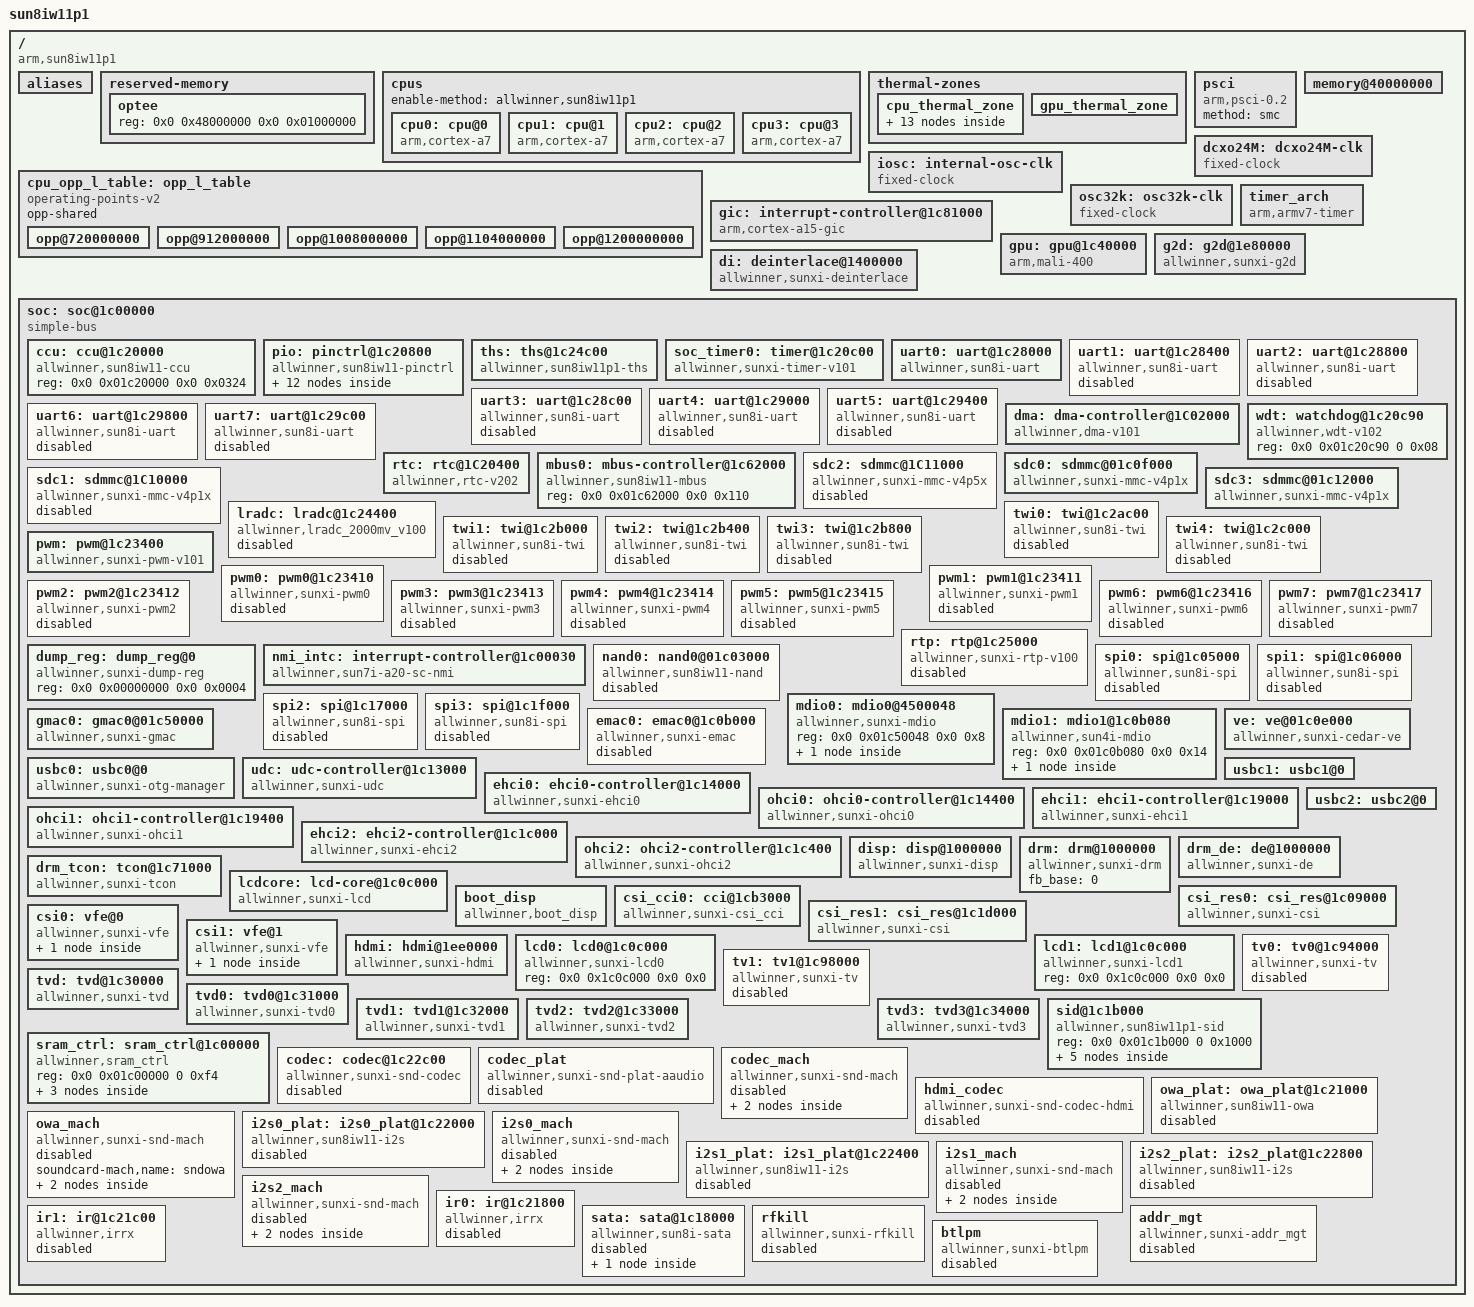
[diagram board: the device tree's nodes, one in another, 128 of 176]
/*
 * Allwinner Technology CO., Ltd. sun8iw11p1 platform
 *
 * fpga support
 * modify base on juno.dts & sun8iw10
 */
/* kernel used */
/memreserve/ 0x43000000 0x00000800; /* super standby range  : [0x43000000~0x43000800], size = 2K  */
/memreserve/ 0x47A00000 0x100000; /* ion carvout heap revserve  : [0x58000000~0x68000000], size = 256M  */

#include <dt-bindings/interrupt-controller/arm-gic.h>
#include <dt-bindings/gpio/gpio.h>
#include <dt-bindings/display/lcd_command.h>
#include <dt-bindings/clock/sun8iw11-ccu.h>
#include <dt-bindings/reset/sun8iw11-ccu.h>

/ {
	model = "sun8iw11p1";
	compatible = "arm,sun8iw11p1", "arm,sun8iw11p1";
	interrupt-parent = <&gic>;
	#address-cells = <2>;
	#size-cells = <2>;

	aliases {
		serial0 = &uart0;
		serial1 = &uart1;
		serial2 = &uart2;
		serial3 = &uart3;
		serial4 = &uart4;
		serial5 = &uart5;
		serial6 = &uart6;
		serial7 = &uart7;
		spi0 = &spi0;
		spi1 = &spi1;
		spi2 = &spi2;
		spi3 = &spi3;
		pio = &pio;
		pwm = &pwm;
		pwm0 = &pwm0;
		pwm1 = &pwm1;
		pwm2 = &pwm2;
		pwm3 = &pwm3;
		pwm4 = &pwm4;
		pwm5 = &pwm5;
		pwm6 = &pwm6;
		pwm7 = &pwm7;
		twi0 = &twi0;
		twi1 = &twi1;
		twi2 = &twi2;
		twi3 = &twi3;
		twi4 = &twi4;
		sunxi-mmc0 = &sdc0;
		sunxi-mmc2 = &sdc2;
		disp = &disp;
		lcd0 = &lcd0;
		lcd1 = &lcd1;
		tv0 = &tv0;
		tv1 = &tv1;
		boot_disp = &boot_disp;
		hdmi = &hdmi;
		drm = &drm;
		ir0 = &ir0;
		ir1 = &ir1;
		sata = &sata;
		nand0 = &nand0;
		cci0 = &csi_cci0;
		csi_res0 = &csi_res0;
		csi_res1 = &csi_res1;
		vfe0 = &csi0;
		vfe1 = &csi1;
		gmac0 = &gmac0;
		emac0 = &emac0;
	};

	reserved-memory {
		#address-cells = <2>;
		#size-cells = <2>;
		ranges;

		optee {
			reg = <0x0 0x48000000 0x0 0x01000000>;
		};
	};

	cpus {
		enable-method = "allwinner,sun8iw11p1";
		#address-cells = <1>;
		#size-cells = <0>;

		cpu0: cpu@0 {
			device_type = "cpu";
			compatible = "arm,cortex-a7","arm,armv7";
			reg = <0x0>;
			enable-method = "psci";
			clocks = <&ccu CLK_CPUX>;
			clock-latency = <2000000>;
			clock-frequency = <1008000000>;
			operating-points-v2 = <&cpu_opp_l_table>;
			#cooling-cells = <2>;
		};

		cpu1: cpu@1 {
			device_type = "cpu";
			compatible = "arm,cortex-a7","arm,armv7";
			reg = <0x1>;
			enable-method = "psci";
			clocks = <&ccu CLK_CPUX>;
			clock-frequency = <1008000000>;
			operating-points-v2 = <&cpu_opp_l_table>;
			#cooling-cells = <2>;
		};

		cpu2: cpu@2 {
			device_type = "cpu";
			compatible = "arm,cortex-a7","arm,armv7";
			reg = <0x2>;
			enable-method = "psci";
			clocks = <&ccu CLK_CPUX>;
			clock-frequency = <1008000000>;
			operating-points-v2 = <&cpu_opp_l_table>;
			#cooling-cells = <2>;
		};

		cpu3: cpu@3 {
			device_type = "cpu";
			compatible = "arm,cortex-a7","arm,armv7";
			reg = <0x3>;
			enable-method = "psci";
			clocks = <&ccu CLK_CPUX>;
			clock-frequency = <1008000000>;
			operating-points-v2 = <&cpu_opp_l_table>;
			#cooling-cells = <2>;
		};
	};

	cpu_opp_l_table: opp_l_table {
		compatible = "operating-points-v2";
		opp-shared;

		opp@720000000 {
			opp-hz = /bits/ 64 <720000000>;
			opp-microvolt = <1060000>;
			clock-latency-ns = <244144>; /* 8 32k periods */
		};
		opp@912000000 {
			opp-hz = /bits/ 64 <912000000>;
			opp-microvolt = <1160000>;
			clock-latency-ns = <244144>; /* 8 32k periods */
		};
		opp@1008000000 {
			opp-hz = /bits/ 64 <1008000000>;
			opp-microvolt = <1220000>;
			clock-latency-ns = <244144>; /* 8 32k periods */
		};
		opp@1104000000 {
			opp-hz = /bits/ 64 <1104000000>;
			opp-microvolt = <1300000>;
			clock-latency-ns = <244144>; /* 8 32k periods */
		};
		opp@1200000000 {
			opp-hz = /bits/ 64 <1200000000>;
			opp-microvolt = <1360000>;
			clock-latency-ns = <244144>; /* 8 32k periods */
		};
	};

	thermal-zones {
		cpu_thermal_zone {
			polling-delay-passive = <1000>;
			polling-delay = <10000>;
			thermal-sensors = <&ths 0>;

			trips {
				cpu_trip0: t0 {
					temperature = <95000>;
					hysteresis = <0>;
					type = "passive";
				};

				cpu_trip1: t1 {
					temperature = <105000>;
					hysteresis = <0>;
					type = "passive";
				};

				cpu_trip2: t2 {
					temperature = <112000>;
					hysteresis = <0>;
					type = "passive";
				};

				cpu_trip3: t3 {
					temperature = <114000>;
					hysteresis = <0>;
					type = "passive";
				};

				cpu_trip4: t4 {
					temperature = <117000>;
					hysteresis = <0>;
					type = "passive";
				};

				crt_trip0: t5 {
					temperature = <120000>;
					hysteresis = <0>;
					type = "critical";
				};
			};

			cooling-maps {
				map0 {
					trip = <&cpu_trip0>;
					cooling-device = <&cpu0 1 1>,
							 <&cpu1 1 1>,
							 <&cpu2 1 1>,
							 <&cpu3 1 1>;
				};

				map1 {
					trip = <&cpu_trip1>;
					cooling-device = <&cpu0 2 2>,
							 <&cpu1 2 2>,
							 <&cpu2 2 2>,
							 <&cpu3 2 2>;
				};

				map2 {
					trip = <&cpu_trip2>;
					cooling-device = <&cpu0 3 3>,
							 <&cpu1 3 3>,
							 <&cpu2 3 3>,
							 <&cpu3 3 3>;
				};

				map3 {
					trip = <&cpu_trip3>;
					cooling-device = <&cpu0 4 4>,
							 <&cpu1 4 4>,
							 <&cpu2 4 4>,
							 <&cpu3 4 4>;
				};

				map4 {
					trip = <&cpu_trip4>;
					cooling-device = <&cpu0 5 5>,
							 <&cpu1 5 5>,
							 <&cpu2 5 5>,
							 <&cpu3 5 5>;
				};
			};
		};

		gpu_thermal_zone {
			polling-delay-passive = <1000>;
			polling-delay = <10000>;
			thermal-sensors = <&ths 1>;
		};
	};

	psci {
		compatible = "arm,psci-0.2";
		method = "smc";
	};

	memory@40000000 {
		device_type = "memory";
		reg = <0x00000000 0x40000000 0x00000000 0x08000000>;
	};

	dcxo24M: dcxo24M-clk {
		#clock-cells = <0>;
		compatible = "fixed-clock";
		clock-frequency = <24000000>;
		clock-output-names = "dcxo24M";
	};
	iosc: internal-osc-clk {
		#clock-cells = <0>;
		compatible = "fixed-clock";
		clock-frequency = <16000000>;
		clock-accuracy = <300000000>;
		clock-output-names = "iosc";
	};

	osc32k: osc32k-clk {
		#clock-cells = <0>;
		compatible = "fixed-clock";
		clock-frequency = <32768>;
		clock-output-names = "osc32k";
	};

	gic: interrupt-controller@1c81000 {
		compatible = "arm,cortex-a15-gic", "arm,cortex-a9-gic";
		#interrupt-cells = <3>;
		#address-cells = <0>;
		device_type = "gic";
		interrupt-controller;
		reg = <0x0 0x01c81000 0 0x1000>, /* GIC Dist */
			 <0x0 0x01c82000 0 0x2000>, /* GIC CPU */
			 <0x0 0x01c84000 0 0x2000>, /* GIC VCPU Control */
			 <0x0 0x01c86000 0 0x2000>; /* GIC VCPU */
		interrupts = <GIC_PPI 9 0xf04>; /* GIC Maintenence IRQ */
		interrupt-parent = <&gic>;
	};

	timer_arch {
		compatible = "arm,armv7-timer";
		interrupts = <GIC_PPI 13 (GIC_CPU_MASK_SIMPLE(4) | IRQ_TYPE_LEVEL_LOW)>,
			     <GIC_PPI 14 (GIC_CPU_MASK_SIMPLE(4) | IRQ_TYPE_LEVEL_LOW)>;
		clock-frequency = <24000000>;
		arm,cpu-registers-not-fw-configured;
		interrupt-parent = <&gic>;
		arm,no-tick-in-suspend;
	};

	gpu: gpu@1c40000 {
		compatible = "arm,mali-400", "arm,mali-utgard";
		reg = <0x0 0x01c40000 0x0 0x10000>;
		interrupts = <GIC_SPI 69 IRQ_TYPE_LEVEL_HIGH>,
					<GIC_SPI 70 IRQ_TYPE_LEVEL_HIGH>,
					<GIC_SPI 71 IRQ_TYPE_LEVEL_HIGH>,
					<GIC_SPI 72 IRQ_TYPE_LEVEL_HIGH>,
					<GIC_SPI 74 IRQ_TYPE_LEVEL_HIGH>,
					<GIC_SPI 75 IRQ_TYPE_LEVEL_HIGH>;
		interrupt-names = "IRQGP", "IRQGPMMU", "IRQPP0", "IRQPPMMU0", "IRQPP1", "IRQPPMMU1";
		clocks = <&ccu CLK_BUS_GPU>, <&ccu CLK_PLL_GPU>, <&ccu CLK_GPU>;
		clock-names = "bus", "pll", "core";
		resets = <&ccu RST_BUS_GPU>;
	};

	g2d: g2d@1e80000 {
		compatible = "allwinner,sunxi-g2d";
		reg = <0x0 0x01e80000 0x0 0x800>;
		interrupts = <GIC_SPI 46 IRQ_TYPE_LEVEL_HIGH>;
		clocks = <&ccu CLK_BUS_MP>, <&ccu CLK_DE_MP>, <&ccu CLK_MP_GATE>;
		clock-names = "bus", "g2d", "mbus_g2d";

		resets = <&ccu RST_BUS_MP>;
		reset-names = "rst_bus_mp";

		assigned-clocks = <&ccu CLK_DE_MP>;
		assigned-clock-parents = <&ccu CLK_PLL_DE>;
		assigned-clock-rates = <297000000>;
		status = "okay";
	};

	di:deinterlace@1400000{
		#address-cells = <1>;
		#size-cells = <0>;
		compatible = "allwinner,sunxi-deinterlace";
		reg = <0x0 0x01400000 0x0 0x77c>;
		interrupts = <GIC_SPI 93 IRQ_TYPE_LEVEL_HIGH>;
		status = "okay";

		clocks = <&ccu CLK_DEINTERLACE>,
			 <&ccu CLK_BUS_DI>,
			 <&ccu CLK_PLL_PERIPH0_1X>,
			 <&ccu CLK_DI_GATE>;
		clock-names = "clk_di",
			      "clk_bus_di",
			      "clk_pll_di",
			      "dclk_gate_di";
		resets = <&ccu RST_BUS_DI>;
		reset-names = "rst_bus_di";

		assigned-clocks = <&ccu CLK_DEINTERLACE>;
		assigned-clock-parents = <&ccu CLK_PLL_PERIPH0_1X>;
	};

	soc: soc@1c00000 {
		compatible = "simple-bus";
		#address-cells = <2>;
		#size-cells = <2>;
		ranges;
		device_type = "soc";

		ccu: ccu@1c20000 {
			compatible = "allwinner,sun8iw11-ccu";
			reg = <0x0 0x01c20000 0x0 0x0324>;  /*cpux space*/
			#clock-cells = <1>;
			#reset-cells = <1>;
		};

		pio: pinctrl@1c20800 {
			compatible = "allwinner,sun8iw11-pinctrl";
			reg = <0x0 0x01c20800 0x0 0x400>;
			interrupts = <GIC_SPI 28 IRQ_TYPE_LEVEL_HIGH>;
			clocks = <&ccu CLK_APB1>, <&dcxo24M>, <&ccu CLK_BUS_PIO>;
			clock-names = "apb", "hosc", "bus";
			gpio-controller;
			#gpio-cells = <3>;
			interrupt-controller;
			#interrupt-cells = <3>;

			lvds0_pins_a: lvds0@0 {
				pins = "PD0", "PD1", "PD2", "PD3", "PD4", "PD5", "PD8", "PD9", "PD6", "PD7";
				function = "lvds0";
				drive-strength = <30>;
			};

			lvds0_pins_b: lvds0@1 {
				pins = "PD0", "PD1", "PD2", "PD3", "PD4", "PD5", "PD8", "PD9", "PD6", "PD7";
				function = "gpio_in";
			};

			lvds1_pins_a: lvds1@0 {
				pins = "PD10", "PD11", "PD12", "PD13", "PD14", "PD15", "PD18", "PD19", "PD16", "PD17";
				function = "lvds1";
				drive-strength = <30>;
			};
			lvds1_pins_b: lvds1@1 {
				pins = "PD10", "PD11", "PD12", "PD13", "PD14", "PD15", "PD18", "PD19", "PD16", "PD17";
				function = "gpio_in";
			};

			csi0_pins_a: csi0@0 {
				pins = "PE0", "PE2", "PE3", "PE4",
						 "PE5", "PE6", "PE7", "PE8",
						 "PE9", "PE10", "PE11";
				function = "csi0";
				drive-strength = <20>;
			};

			csi0_pins_b: csi0@1 {
				pins = "PE0", "PE2", "PE3", "PE4",
						 "PE5", "PE6", "PE7", "PE8",
						 "PE9", "PE10", "PE11";
				function = "io_disabled";
			};

			csi_mclk0_pins_a: csi_mclk0@0 {
				pins = "PE1";
				function = "csi0";
				drive-strength = <20>;
			};

			csi_mclk0_pins_b: csi_mclk0@1 {
				pins = "PE1";
				function = "gpio_in";
			};

			csi1_pins_a: csi1@0 {
				pins = "PG0", "PG2", "PG3", "PG4",
						 "PG5", "PG6", "PG7", "PG8",
						 "PG9", "PG10", "PG11";
				function = "csi1";
				drive-strength = <10>;
			};

			csi1_pins_b: csi1@1 {
				pins = "PG0", "PG2", "PG3", "PG4",
						 "PG5", "PG6", "PG7", "PG8",
						 "PG9", "PG10", "PG11";
				function = "io_disabled";
			};

			csi_mclk1_pins_a: csi_mclk1@0 {
				pins = "PG1";
				function = "csi1";
				drive-strength = <20>;
			};

			csi_mclk1_pins_b: csi_mclk1@1 {
				pins = "PG1";
				function = "gpio_in";
			};

		};

		ths: ths@1c24c00 {
			compatible = "allwinner,sun8iw11p1-ths";
			reg = <0x0 0x01c24c00 0x0 0x400>;
			clocks = <&ccu CLK_BUS_THS>, <&ccu CLK_THS>;
			clock-names = "bus", "sclk";
			resets = <&ccu RST_BUS_THS>;
			#thermal-sensor-cells = <1>;
		};

		soc_timer0: timer@1c20c00 {
			compatible = "allwinner,sunxi-timer-v101";
			device_type = "soc_timer";
			reg = <0x0 0x01c20c00 0x0 0x90>;
			interrupt-parent = <&gic>;
			interrupts = <GIC_SPI 22 IRQ_TYPE_EDGE_RISING>;
			clocks = <&dcxo24M>;
		};

		uart0: uart@1c28000 {
			compatible = "allwinner,sun8i-uart";
			device_type = "uart0";
			reg = <0x0 0x01c28000 0x0 0x400>;
			interrupts = <GIC_SPI 1 IRQ_TYPE_LEVEL_HIGH>;
			clocks = <&ccu CLK_BUS_UART0>;
			resets = <&ccu RST_BUS_UART0>;
			uart0_port = <0>;
			uart0_type = <2>;
			sunxi,uart-fifosize = <64>;
			status = "okay";
		};

		uart1: uart@1c28400 {
			compatible = "allwinner,sun8i-uart";
			device_type = "uart1";
			reg = <0x0 0x01c28400 0x0 0x400>;
			interrupts = <GIC_SPI 2 IRQ_TYPE_LEVEL_HIGH>;
			clocks = <&ccu CLK_BUS_UART1>;
			resets = <&ccu RST_BUS_UART1>;
			uart1_port = <1>;
			uart1_type = <8>;
			sunxi,uart-fifosize = <64>;
			status = "disabled";
		};

		uart2: uart@1c28800 {
			compatible = "allwinner,sun8i-uart";
			device_type = "uart2";
			reg = <0x0 0x01c28800 0x0 0x400>;
			interrupts = <GIC_SPI 3 IRQ_TYPE_LEVEL_HIGH>;
			clocks = <&ccu CLK_BUS_UART2>;
			resets = <&ccu RST_BUS_UART2>;
			uart2_port = <2>;
			uart2_type = <4>;
			sunxi,uart-fifosize = <64>;
			status = "disabled";
		};

		uart3: uart@1c28c00 {
			compatible = "allwinner,sun8i-uart";
			device_type = "uart3";
			reg = <0x0 0x01c28c00 0x0 0x400>;
			interrupts = <GIC_SPI 4 IRQ_TYPE_LEVEL_HIGH>;
			clocks = <&ccu CLK_BUS_UART3>;
			resets = <&ccu RST_BUS_UART3>;
			uart3_port = <3>;
			uart3_type = <4>;
			sunxi,uart-fifosize = <64>;
			status = "disabled";
		};

		uart4: uart@1c29000 {
			compatible = "allwinner,sun8i-uart";
			device_type = "uart4";
			reg = <0x0 0x01c29000 0x0 0x400>;
			interrupts = <GIC_SPI 17 IRQ_TYPE_LEVEL_HIGH>;
			clocks = <&ccu CLK_BUS_UART4>;
			resets = <&ccu RST_BUS_UART4>;
			uart4_port = <4>;
			uart4_type = <2>;
			sunxi,uart-fifosize = <64>;
			status = "disabled";
		};

		uart5: uart@1c29400 {
			compatible = "allwinner,sun8i-uart";
			device_type = "uart5";
			reg = <0x0 0x01c29400 0x0 0x400>;
			interrupts = <GIC_SPI 18 IRQ_TYPE_LEVEL_HIGH>;
			clocks = <&ccu CLK_BUS_UART5>;
			resets = <&ccu RST_BUS_UART5>;
			uart5_port = <5>;
			uart5_type = <2>;
			sunxi,uart-fifosize = <64>;
			status = "disabled";
		};

		uart6: uart@1c29800 {
			compatible = "allwinner,sun8i-uart";
			device_type = "uart6";
			reg = <0x0 0x01c29800 0x0 0x400>;
			interrupts = <GIC_SPI 19 IRQ_TYPE_LEVEL_HIGH>;
			clocks = <&ccu CLK_BUS_UART6>;
			resets = <&ccu RST_BUS_UART6>;
			uart6_port = <6>;
			uart6_type = <2>;
			sunxi,uart-fifosize = <64>;
			status = "disabled";
		};

		uart7: uart@1c29c00 {
			compatible = "allwinner,sun8i-uart";
			device_type = "uart7";
			reg = <0x0 0x01c29c00 0x0 0x400>;
			interrupts = <GIC_SPI 20 IRQ_TYPE_LEVEL_HIGH>;
			clocks = <&ccu CLK_BUS_UART7>;
			resets = <&ccu RST_BUS_UART7>;
			uart7_port = <7>;
			uart7_type = <2>;
			sunxi,uart-fifosize = <64>;
			status = "disabled";
		};


		dma: dma-controller@1C02000 {
			compatible = "allwinner,dma-v101";
			reg = <0x0 0x01C02000 0x0 0x1000>;
			interrupts = <GIC_SPI 27 IRQ_TYPE_LEVEL_HIGH>;
			clocks = <&ccu CLK_BUS_DMA>;
			clock-names = "bus";
			resets = <&ccu RST_BUS_DMA>;
			dma-channels = <16>;
			dma-requests = <32>;
			#dma-cells = <1>;
		};

		wdt: watchdog@1c20c90 {
			compatible = "allwinner,wdt-v102";
			reg = <0x0 0x01c20c90 0 0x08>;
		};

		rtc: rtc@1C20400 {
			compatible = "allwinner,rtc-v202";
			device_type = "rtc";
			wakeup-source;
			reg = <0x0 0x01C20400 0x0 0x200>;
			interrupts = <GIC_SPI 24 IRQ_TYPE_LEVEL_HIGH>;
			clocks = <&osc32k>;
			clock-names = "r-ahb-rtc";
			gpr_cur_pos = <6>;
		};

		mbus0: mbus-controller@1c62000 {
			compatible = "allwinner,sun8iw11-mbus";
			reg = <0x0 0x01c62000 0x0 0x110>;
			#mbus-cells = <1>;
		};

		sdc2: sdmmc@1C11000 {
			compatible = "allwinner,sunxi-mmc-v4p5x";
			device_type = "sdc2";
			reg = <0x0 0x01C11000 0x0 0x1000>;
			interrupts = <GIC_SPI 34 0x0104>;  /*  */
			clocks = <&dcxo24M>,
			<&ccu CLK_PLL_PERIPH1_2X>,
			<&ccu CLK_MMC2>,
			<&ccu CLK_BUS_MMC2>;
			clock-names = "osc24m","pll_periph","mmc","ahb";
			resets = <&ccu RST_BUS_MMC2>;
			reset-names = "rst";
			pinctrl-names = "default","sleep";
			pinctrl-0 = <&sdc2_pins_a &sdc2_pins_c>;
			pinctrl-1 = <&sdc2_pins_b>;
			bus-width = <8>;
			/*mmc-ddr-1_8v;*/
			/*mmc-hs200-1_8v;*/
			/*mmc-hs400-1_8v;*/
			non-removable;
			/*max-frequency = <200000000>;*/
			max-frequency = <50000000>;
			cd-gpios;
			sunxi-power-save-mode;
			sunxi-dis-signal-vol-sw;
			/*vmmc = "vcc-emmcv";
			vqmmc = "vcc-emmcvq18";
			vdmmc = "none";*/
			/*-- speed mode --*/
			/*sm0: DS26_SDR12*/
			/*sm1: HSSDR52_SDR25*/
			/*sm2: HSDDR52_DDR50*/
			/*sm3: HS200_SDR104*/
			/*sm4: HS400*/
			/*-- frequency point --
			/*f0: CLK_400K*/
			/*f1: CLK_25M*/
			/*f2: CLK_50M*/
			/*f3: CLK_100M*/
			/*f4: CLK_150M*/
			/*f5: CLK_200M*/
			sdc_tm4_sm0_freq0 = <0>;
			sdc_tm4_sm0_freq1 = <0>;
			sdc_tm4_sm1_freq0 = <0x00000000>;
			sdc_tm4_sm1_freq1 = <0>;
			sdc_tm4_sm2_freq0 = <0x00000000>;
			sdc_tm4_sm2_freq1 = <0>;
			sdc_tm4_sm3_freq0 = <0x05000000>;
			sdc_tm4_sm3_freq1 = <0x00000005>;
			sdc_tm4_sm4_freq0 = <0x00050000>;
			sdc_tm4_sm4_freq1 = <0x00000004>;
			/*vmmc-supply = <&reg_3p3v>;*/
			/*vqmc-supply = <&reg_3p3v>;*/
			/*vdmc-supply = <&reg_3p3v>;*/
			/*vmmc = "vcc-card";*/
			/*vqmc = "";*/
			/*vdmc = "";*/
			/*sunxi-power-save-mode;*/
			status = "disabled";
			/*status = "okay";*/

		};

		sdc0: sdmmc@01c0f000 {
			compatible = "allwinner,sunxi-mmc-v4p1x";
			device_type = "sdc0";
			reg = <0x0 0x01c0f000 0x0 0x1000>; /* only sdmmc0 */
			interrupts = <GIC_SPI 32 0x0104>;  /*  */
			clocks =  <&dcxo24M>,
					<&ccu CLK_PLL_PERIPH1_2X>,
					<&ccu CLK_MMC0>,
					<&ccu CLK_BUS_MMC0>;
			clock-names = "osc24m","pll_periph","mmc","ahb";
			resets = <&ccu RST_BUS_MMC0>;
			reset-names = "rst";
			pinctrl-names = "default","sleep";
			pinctrl-0 = <&sdc0_pins_a>;
			pinctrl-1 = <&sdc0_pins_b>;
			max-frequency = <50000000>;
			bus-width = <4>;
			/*cd-inverted*/
			cd-gpios = <&pio PF 6 0 1 2 0>;
			/* vmmc-supply = <&reg_3p3v>;*/
			/* vqmc-supply = <&reg_3p3v>;*/
			/* vdmc-supply = <&reg_3p3v>;*/
			/*vmmc = "vcc-card";*/
			/*vqmc = "";*/
			/*vdmc = "";*/
			/*sd-uhs-sdr50;*/
			/*sd-uhs-ddr50;*/
			/*cap-sdio-irq;*/
			/*keep-power-in-suspend;*/
			/*ignore-pm-notify;*/
			/*sunxi-power-save-mode;*/
			/*sunxi-dly-400k = <1 0 0 0>; */
			/*sunxi-dly-26M  = <1 0 0 0>;*/
			/*sunxi-dly-52M  = <1 0 0 0 1>;*/
			/*sunxi-dly-52M-ddr4  = <1 0 0 0>;*/
			/*sunxi-dly-52M-ddr8  = <1 0 0 0>;*/
			/*sunxi-dly-104M  = <1 0 0 0>;*/
			/*sunxi-dly-208M  = <1 0 0 0>;*/
			/*sunxi-dly-104M-ddr  = <1 0 0 0>;*/
			/*sunxi-dly-208M-ddr  = <1 0 0 0>;*/
			status = "okay";
		};

		sdc1: sdmmc@1C10000 {
			compatible = "allwinner,sunxi-mmc-v4p1x";
			device_type = "sdc1";
			reg = <0x0 0x1C10000 0x0 0x1000>;
			interrupts = <GIC_SPI 33 0x0104>;  /*  */
			clocks = <&dcxo24M>,
			    <&ccu CLK_PLL_PERIPH1_2X>,
			    <&ccu CLK_MMC1>,
			    <&ccu CLK_BUS_MMC1>;
			clock-names = "osc24m","pll_periph","mmc","ahb";
			resets = <&ccu RST_BUS_MMC1>;
			reset-names = "rst";
			pinctrl-names = "default","sleep";
			pinctrl-0 = <&sdc1_pins_a>;
			pinctrl-1 = <&sdc1_pins_b>;
			max-frequency = <50000000>;
			bus-width = <4>;
			/*broken-cd;*/
			/*cd-inverted*/
			/*cd-gpios = <&pio PG 6 6 1 2 0>;*/
			/* vmmc-supply = <&reg_3p3v>;*/
			/* vqmc-supply = <&reg_3p3v>;*/
			/* vdmc-supply = <&reg_3p3v>;*/
			/*vmmc = "vcc-card";*/
			/*vqmc = "";*/
			/*vdmc = "";*/
			/*sd-uhs-sdr50;*/
			/*sd-uhs-ddr50;*/
			/*sd-uhs-sdr104;*/
			/*cap-sdio-irq;*/
			/*keep-power-in-suspend;*/
			/*ignore-pm-notify;*/
			/*sunxi-power-save-mode;*/
			/*sunxi-dly-400k = <1 0 0 0 0>; */
			/*sunxi-dly-26M  = <1 0 0 0 0>;*/
			/*sunxi-dly-52M  = <1 0 0 0 0>;*/
			/*sunxi-dly-52M-ddr4  = <1 0 0 0 2>;*/
			/*sunxi-dly-52M-ddr8  = <1 0 0 0 0>;*/
			/*sunxi-dly-104M  = <1 0 0 0 1>;*/
			/*sunxi-dly-208M  = <1 1 0 0 0>;*/
			/*sunxi-dly-208M  = <1 0 0 0 1>;*/
			/*sunxi-dly-104M-ddr  = <1 0 0 0 0>;*/
			/*sunxi-dly-208M-ddr  = <1 0 0 0 0>;*/
			/*status = "okay";*/
			status = "disabled";
		};

		sdc3: sdmmc@01c12000 {
			compatible = "allwinner,sunxi-mmc-v4p1x";
			device_type = "sdc3";
			reg = <0x0 0x01C12000 0x0 0x1000>;
			interrupts = <GIC_SPI 35 0x0104>;
			clocks =  <&dcxo24M>,
					<&ccu CLK_PLL_PERIPH1_2X>,
					<&ccu CLK_MMC3>,
					<&ccu CLK_BUS_MMC3>;
			clock-names = "osc24m","pll_periph","mmc","ahb";
			resets = <&ccu RST_BUS_MMC3>;
			reset-names = "rst";
			pinctrl-names = "default","sleep";
			pinctrl-0 = <&sdc3_pins_a>;
			pinctrl-1 = <&sdc3_pins_b>;
			max-frequency = <50000000>;
			bus-width = <4>;
			/*cd-inverted*/
			/* vmmc-supply = <&reg_3p3v>;*/
			/* vqmc-supply = <&reg_3p3v>;*/
			/* vdmc-supply = <&reg_3p3v>;*/
			/*vmmc = "vcc-card";*/
			/*vqmc = "";*/
			/*vdmc = "";*/
			/*sd-uhs-sdr50;*/
			/*sd-uhs-ddr50;*/
			/*cap-sdio-irq;*/
			/*keep-power-in-suspend;*/
			/*ignore-pm-notify;*/
			/*sunxi-power-save-mode;*/
			/*sunxi-dly-400k = <1 0 0 0>; */
			/*sunxi-dly-26M  = <1 0 0 0>;*/
			/*sunxi-dly-52M  = <1 0 0 0 1>;*/
			/*sunxi-dly-52M-ddr4  = <1 0 0 0>;*/
			/*sunxi-dly-52M-ddr8  = <1 0 0 0>;*/
			/*sunxi-dly-104M  = <1 0 0 0>;*/
			/*sunxi-dly-208M  = <1 0 0 0>;*/
			/*sunxi-dly-104M-ddr  = <1 0 0 0>;*/
			/*sunxi-dly-208M-ddr  = <1 0 0 0>;*/
			status = "okay";
		};

		lradc: lradc@1c24400 {
			compatible = "allwinner,lradc_2000mv_v100";
			reg = <0x0 0x01c24400 0x0 0x400>;
			interrupts = <GIC_SPI 31 IRQ_TYPE_EDGE_RISING>;
			status = "disabled";
		};

		twi0: twi@1c2ac00 {
			#address-cells = <1>;
			#size-cells = <0>;
			compatible = "allwinner,sun8i-twi";
			device_type = "twi0";
			reg = <0x0 0x01c2ac00 0x0 0x400>;
			interrupts = <GIC_SPI 7 IRQ_TYPE_LEVEL_HIGH>;
			clocks = <&ccu CLK_BUS_TWI0>;
			clock-names = "bus";
			resets = <&ccu RST_BUS_TWI0>;
			status = "disabled";
		};

		twi1: twi@1c2b000 {
			#address-cells = <1>;
			#size-cells = <0>;
			compatible = "allwinner,sun8i-twi";
			device_type = "twi1";
			reg = <0x0 0x01c2b000 0x0 0x400>;
			interrupts = <GIC_SPI 8 IRQ_TYPE_LEVEL_HIGH>;
			clocks = <&ccu CLK_BUS_TWI1>;
			clock-names = "bus";
			resets = <&ccu RST_BUS_TWI1>;
			status = "disabled";
		};

		twi2: twi@1c2b400 {
			#address-cells = <1>;
			#size-cells = <0>;
			compatible = "allwinner,sun8i-twi";
			device_type = "twi2";
			reg = <0x0 0x01c2b400 0x0 0x400>;
			interrupts = <GIC_SPI 9 IRQ_TYPE_LEVEL_HIGH>;
			clocks = <&ccu CLK_BUS_TWI2>;
			clock-names = "bus";
			resets = <&ccu RST_BUS_TWI2>;
			status = "disabled";
		};

		twi3: twi@1c2b800 {
			#address-cells = <1>;
			#size-cells = <0>;
			compatible = "allwinner,sun8i-twi";
			device_type = "twi3";
			reg = <0x0 0x01c2b800 0x0 0x400>;
			interrupts = <GIC_SPI 88 IRQ_TYPE_LEVEL_HIGH>;
			clocks = <&ccu CLK_BUS_TWI3>;
			clock-names = "bus";
			resets = <&ccu RST_BUS_TWI3>;
			status = "disabled";
		};

		twi4: twi@1c2c000 {
			#address-cells = <1>;
			#size-cells = <0>;
			compatible = "allwinner,sun8i-twi";
			device_type = "twi4";
			reg = <0x0 0x1c2c000 0x0 0x400>;
			interrupts = <GIC_SPI 89 IRQ_TYPE_LEVEL_HIGH>;
			clocks = <&ccu CLK_BUS_TWI4>;
			clock-names = "bus";
			resets = <&ccu RST_BUS_TWI4>;
			status = "disabled";
		};

		pwm: pwm@1c23400 {
			#pwm-cells = <0x3>;
			compatible = "allwinner,sunxi-pwm-v101";
			reg = <0x0 0x01c23400 0x0 0x400>;
			interrupts = <GIC_SPI 47 IRQ_TYPE_EDGE_RISING>;
			pwm-number = <8>;
			pwm-base = <0x0>;
			sunxi-pwms = <&pwm0>, <&pwm1>, <&pwm2>, <&pwm3>, <&pwm4>, <&pwm5>, <&pwm6>, <&pwm7>;
		};

		pwm0: pwm0@1c23410 {
			compatible = "allwinner,sunxi-pwm0";
			reg = <0x0 0x01c23410 0x0 0x4>;
			reg_base = <0x01c23400>;
			status = "disabled";
		};

		pwm1: pwm1@1c23411 {
			compatible = "allwinner,sunxi-pwm1";
			reg = <0x0 0x01c23411 0x0 0x4>;
			reg_base = <0x01c23400>;
			status = "disabled";
		};

		pwm2: pwm2@1c23412 {
			compatible = "allwinner,sunxi-pwm2";
			reg = <0x0 0x01c23412 0x0 0x4>;
			reg_base = <0x01c23400>;
			status = "disabled";
		};

		pwm3: pwm3@1c23413 {
			compatible = "allwinner,sunxi-pwm3";
			reg = <0x0 0x01c23413 0x0 0x4>;
			reg_base = <0x01c23400>;
			status = "disabled";
		};

		pwm4: pwm4@1c23414 {
			compatible = "allwinner,sunxi-pwm4";
			reg = <0x0 0x01c23414 0x0 0x4>;
			reg_base = <0x01c23400>;
			status = "disabled";
		};

		pwm5: pwm5@1c23415 {
			compatible = "allwinner,sunxi-pwm5";
			reg = <0x0 0x01c23415 0x0 0x4>;
			reg_base = <0x01c23400>;
			status = "disabled";
		};

		pwm6: pwm6@1c23416 {
			compatible = "allwinner,sunxi-pwm6";
			reg = <0x0 0x01c23416 0x0 0x4>;
			reg_base = <0x01c23400>;
			status = "disabled";
		};

		pwm7: pwm7@1c23417 {
			compatible = "allwinner,sunxi-pwm7";
			reg = <0x0 0x01c23417 0x0 0x4>;
			reg_base = <0x01c23400>;
			status = "disabled";
		};

		dump_reg: dump_reg@0 {
			compatible = "allwinner,sunxi-dump-reg";
			reg = <0x0 0x00000000 0x0 0x0004>;
		};

		rtp: rtp@1c25000 {
			compatible = "allwinner,sunxi-rtp-v100";
			reg = <0x0 0x01c25000 0x0 0x400>;
			interrupts = <GIC_SPI 29 IRQ_TYPE_EDGE_RISING>;
			status = "disabled";
		};

		nmi_intc: interrupt-controller@1c00030 {
			compatible = "allwinner,sun7i-a20-sc-nmi";
			interrupt-parent = <&gic>;
			interrupt-controller;
			#interrupt-cells = <2>;
			reg = <0x0 0x01c00030 0 0xc>;
			interrupts = <GIC_SPI 0 IRQ_TYPE_LEVEL_HIGH>;
		};

		nand0:nand0@01c03000 {
			compatible = "allwinner,sun8iw11-nand";
			device_type = "nand0";
			reg = <0x0 0x01c03000 0x0 0x1000>; /* nand0 */
			interrupts = <GIC_SPI 37 0x04>;
			clocks = <&ccu CLK_PLL_PERIPH0_1X>, <&ccu CLK_NAND>, <&ccu CLK_BUS_NAND>;
			clock-names = "pll", "mod", "bus";
			nand0_regulator1 = "vcc-nand";
			nand0_regulator2 = "none";
			nand0_cache_level = <0x55aaaa55>;
			nand0_flush_cache_num = <0x55aaaa55>;
			nand0_capacity_level = <0x55aaaa55>;
			nand0_id_number_ctl = <0x55aaaa55>;
			nand0_print_level = <0x55aaaa55>;
			nand0_p0 = <0x55aaaa55>;
			nand0_p1 = <0x55aaaa55>;
			nand0_p2 = <0x55aaaa55>;
			nand0_p3 = <0x55aaaa55>;
			status = "disabled";
		};

		spi0: spi@1c05000 {
			#address-cells = <1>;
			#size-cells = <0>;
			compatible = "allwinner,sun8i-spi";
			device_type = "spi0";
			reg = <0x0 0x01c05000 0x0 0x1000>;
			interrupts = <GIC_SPI 10 IRQ_TYPE_LEVEL_HIGH>;
			clocks = <&ccu CLK_PLL_PERIPH0_1X>, <&ccu CLK_SPI0>, <&ccu CLK_BUS_SPI0>;
			clock-names = "pll", "mod", "bus";
			resets = <&ccu RST_BUS_SPI0>;
			clock-frequency = <100000000>;
			spi0_cs_number = <2>;
			spi0_cs_bitmap = <3>;
			dmas = <&dma 24>, <&dma 24>;
			dma-names = "tx", "rx";
			status = "disabled";
		};

		spi1: spi@1c06000 {
			#address-cells = <1>;
			#size-cells = <0>;
			compatible = "allwinner,sun8i-spi";
			device_type = "spi1";
			reg = <0x0 0x01c06000 0x0 0x1000>;
			interrupts = <GIC_SPI 11 IRQ_TYPE_LEVEL_HIGH>;
			clocks = <&ccu CLK_PLL_PERIPH0_1X>, <&ccu CLK_SPI1>, <&ccu CLK_BUS_SPI1>;
			clock-names = "pll", "mod", "bus";
			resets = <&ccu RST_BUS_SPI1>;
			clock-frequency = <100000000>;
			spi1_cs_number = <2>;
			spi1_cs_bitmap = <3>;
			dmas = <&dma 25>, <&dma 25>;
			dma-names = "tx", "rx";
			status = "disabled";
		};

		spi2: spi@1c17000 {
			#address-cells = <1>;
			#size-cells = <0>;
			compatible = "allwinner,sun8i-spi";
			device_type = "spi2";
			reg = <0x0 0x01c17000 0x0 0x1000>;
			interrupts = <GIC_SPI 12 IRQ_TYPE_LEVEL_HIGH>;
			clocks = <&ccu CLK_PLL_PERIPH0_1X>, <&ccu CLK_SPI2>, <&ccu CLK_BUS_SPI2>;
			clock-names = "pll", "mod", "bus";
			resets = <&ccu RST_BUS_SPI2>;
			clock-frequency = <100000000>;
			spi2_cs_number = <2>;
			spi2_cs_bitmap = <3>;
			dmas = <&dma 26>, <&dma 26>;
			dma-names = "tx", "rx";
			status = "disabled";
		};

		spi3: spi@1c1f000 {
			#address-cells = <1>;
			#size-cells = <0>;
			compatible = "allwinner,sun8i-spi";
			device_type = "spi3";
			reg = <0x0 0x01c1f000 0x0 0x1000>;
			interrupts = <GIC_SPI 50 IRQ_TYPE_LEVEL_HIGH>;
			clocks = <&ccu CLK_PLL_PERIPH0_1X>, <&ccu CLK_SPI3>, <&ccu CLK_BUS_SPI3>;
			clock-names = "pll", "mod", "bus";
			resets = <&ccu RST_BUS_SPI3>;
			clock-frequency = <100000000>;
			spi3_cs_number = <2>;
			spi3_cs_bitmap = <3>;
			dmas = <&dma 27>, <&dma 27>;
			dma-names = "tx", "rx";
			status = "disabled";
		};

		mdio0: mdio0@4500048 {
			compatible = "allwinner,sunxi-mdio";
			#address-cells = <1>;
			#size-cells = <0>;
			reg = <0x0 0x01c50048 0x0 0x8>;
			status = "okay";
			phy0: ethernet-phy@0 {
				/* RTL8211F (0x001cc916) */
				reg = <0>;
				max-speed = <1000>;  /* 1000M */
				reset-gpios = <&pio PA 17 GPIO_ACTIVE_LOW>;
				/* PHY datasheet rst time */
				reset-assert-us = <10000>;
				reset-deassert-us = <150000>;
			};
		};

		gmac0: gmac0@01c50000 {
			compatible = "allwinner,sunxi-gmac";
			reg = <0x0 0x01c50000 0x0 0x1000>,
			    <0x0 0x01c20164 0x0 0x04>;
			interrupts = <GIC_SPI 85 IRQ_TYPE_LEVEL_HIGH>;
			interrupt-names = "gmacirq";
			clocks = <&ccu CLK_BUS_GMAC>;
			clock-names = "gmac";
			resets = <&ccu RST_BUS_GMAC>;
			phy-handle = <&phy0>;
			status = "okay";
		};

		mdio1: mdio1@1c0b080 {
			compatible = "allwinner,sun4i-mdio";
			#address-cells = <1>;
			#size-cells = <0>;
			reg = <0x0 0x01c0b080 0x0 0x14>;
			status = "okay";
			phy1: ethernet-phy@1 {
				reg = <1>;
			};
		};

		emac0: emac0@1c0b000 {
			compatible = "allwinner,sunxi-emac";
			reg = <0x0 0x01c0b000 0x0 0x01000>,
			    <0x0 0x01c00004 0x0 0x4>;
			interrupts      = <GIC_SPI 55 IRQ_TYPE_LEVEL_HIGH>;
			interrupt-names = "emacirq";
			clocks   = <&ccu CLK_BUS_EMAC>;
			clock-names = "emac";
			resets = <&ccu RST_BUS_EMAC>;
			phy-handle = <&phy1>;
			status = "disabled";
		};

		ve: ve@01c0e000 {
			compatible = "allwinner,sunxi-cedar-ve";
			reg = <0x0 0x01c0e000 0x0 0x1000>,
			      <0x0 0x01c00000 0x0 0x10>,
			      <0x0 0x01c20000 0x0 0x800>;
			interrupts = <GIC_SPI 53 IRQ_TYPE_LEVEL_HIGH>;
			clocks = <&ccu CLK_VE> ,<&ccu CLK_BUS_VE >,<&ccu CLK_VE_GATE>;
			clock-names =  "ve","bus_ve","mbus_ve";
			resets = <&ccu RST_BUS_VE>;
		};

		usbc0: usbc0@0 {
			device_type = "usbc0";
			compatible = "allwinner,sunxi-otg-manager";
			usb_port_type = <2>;
			usb_detect_type = <1>;
			usb_detect_mode = <0>;
			usb_id_gpio;
			usb_det_vbus_gpio;
			usb_drv_vbus_gpio;
			usb_regulator_io = "nocare";
			usb_wakeup_suspend = <0>;
			usb_luns = <3>;
			usb_serial_unique = <0>;
			usb_serial_number = "20080411";
			rndis_wceis = <1>;
		};

		udc: udc-controller@1c13000 {
			compatible = "allwinner,sunxi-udc";
			reg = <0x0 0x01c13000 0x0 0x1000>, /*udc base*/
			      <0x0 0x01c00000 0x0 0x100>; /*sram base*/
			interrupts = <GIC_SPI 38 IRQ_TYPE_LEVEL_HIGH>;
			interrupt-parent = <&gic>;
			clocks = <&ccu CLK_BUS_OTG>, <&ccu CLK_USBPHY0_GATE>;
			clock-names = "bus_otg", "phy";
			resets = <&ccu RST_BUS_USBOTG>, <&ccu RST_BUS_USBPHY0>;
			reset-names = "otg", "phy";
		};

		ehci0: ehci0-controller@1c14000 {
			compatible = "allwinner,sunxi-ehci0";
			reg = <0x0 0x01c14000 0x0 0xFFF>, /*hci0 base*/
			      <0x0 0x01c00000 0x0 0x100>, /*sram base*/
			      <0x0 0x01c13000 0x0 0x1000>; /*otg base*/
			interrupts = <GIC_SPI 39 IRQ_TYPE_LEVEL_HIGH>;
			clocks = <&ccu CLK_BUS_EHCI0>, <&ccu CLK_USBPHY0_GATE>;
			clock-names = "bus_hci", "phy";
			resets = <&ccu RST_BUS_USBEHCI0>, <&ccu RST_BUS_USBPHY0>;
			reset-names = "hci", "phy";
			hci_ctrl_no = <0>;
		};

		ohci0: ohci0-controller@1c14400 {
			compatible = "allwinner,sunxi-ohci0";
			reg = <0x0 0x01c14400 0x0 0xFFF>, /*hci0 base*/
			      <0x0 0x01c00000 0x0 0x100>, /*sram base*/
			      <0x0 0x01c13000 0x0 0x1000>; /*otg base*/
			interrupts = <GIC_SPI 40 IRQ_TYPE_LEVEL_HIGH>;
			clocks = <&ccu CLK_USB_OHCI0>, <&ccu CLK_OHCI0_12M>, <&ccu CLK_USBPHY0_GATE>,
				 <&ccu CLK_12M_FROM_48M>,<&ccu CLK_12M_FROM_24M>,<&ccu CLK_12M_FROM_32K>;
			clock-names = "bus_hci", "ohci", "phy","hoscx2","hosc","losc";
			resets = <&ccu RST_BUS_USBOHCI0>, <&ccu RST_BUS_USBPHY0>;
			reset-names = "hci", "phy";
			hci_ctrl_no = <0>;
		};

		usbc1: usbc1@0 {
			device_type = "usbc1";
			usb_drv_vbus_gpio;
			usb_regulatior_io = "nocare";
			usb_wakeup_suspend = <0>;
		};

		ehci1: ehci1-controller@1c19000 {
			compatible = "allwinner,sunxi-ehci1";
			reg = <0x0 0x01c19000 0x0 0xFFF>, /*hci1 base*/
			      <0x0 0x01c00000 0x0 0x100>, /*sram base*/
			      <0x0 0x01c13000 0x0 0x1000>; /*otg base*/
			interrupts = <GIC_SPI 76 IRQ_TYPE_LEVEL_HIGH>;
			clocks = <&ccu CLK_BUS_EHCI1>, <&ccu CLK_USBPHY1_GATE>;
			clock-names = "bus_hci", "phy";
			resets = <&ccu RST_BUS_USBEHCI1>, <&ccu RST_BUS_USBPHY1>;
			reset-names = "hci", "phy";
			hci_ctrl_no = <1>;
		};

		ohci1: ohci1-controller@1c19400 {
			compatible = "allwinner,sunxi-ohci1";
			reg = <0x0 0x01c19400 0x0 0xFFF>, /*hci1 base*/
			      <0x0 0x01c00000 0x0 0x100>, /*sram base*/
			      <0x0 0x01c13000 0x0 0x1000>; /*otg base*/
			interrupts = <GIC_SPI 64 IRQ_TYPE_LEVEL_HIGH>;
			clocks = <&ccu CLK_USB_OHCI1>, <&ccu CLK_OHCI1_12M>, <&ccu CLK_USBPHY1_GATE>,
				 <&ccu CLK_12M_FROM_48M>,<&ccu CLK_12M_FROM_24M>,<&ccu CLK_12M_FROM_32K>;
			clock-names = "bus_hci", "ohci", "phy","hoscx2","hosc","losc";
			resets = <&ccu RST_BUS_USBOHCI1>, <&ccu RST_BUS_USBPHY1>;
			reset-names = "hci", "phy";
			hci_ctrl_no = <1>;
		};

		usbc2: usbc2@0 {
			device_type = "usbc2";
			usb_drv_vbus_gpio;
			usb_regulatior_io = "nocare";
			usb_wakeup_suspend = <0>;
		};

		ehci2: ehci2-controller@1c1c000 {
			compatible = "allwinner,sunxi-ehci2";
			reg = <0x0 0x01c1c000 0x0 0xFFF>, /*hci2 base*/
			      <0x0 0x01c00000 0x0 0x100>, /*sram base*/
			      <0x0 0x01c13000 0x0 0x1000>; /*otg base*/
			interrupts = <GIC_SPI 78 IRQ_TYPE_LEVEL_HIGH>;
			clocks = <&ccu CLK_BUS_EHCI2>, <&ccu CLK_USBPHY2_GATE>;
			clock-names = "bus_hci", "phy";
			resets = <&ccu RST_BUS_USBEHCI2>, <&ccu RST_BUS_USBPHY2>;
			reset-names = "hci", "phy";
			hci_ctrl_no = <2>;
		};

		ohci2: ohci2-controller@1c1c400 {
			compatible = "allwinner,sunxi-ohci2";
			reg = <0x0 0x01c1c400 0x0 0xFFF>, /*hci2 base*/
			      <0x0 0x01c00000 0x0 0x100>, /*sram base*/
			      <0x0 0x01c13000 0x0 0x1000>; /*otg base*/
			interrupts = <GIC_SPI 65 IRQ_TYPE_LEVEL_HIGH>;
			clocks = <&ccu CLK_USB_OHCI2>, <&ccu CLK_OHCI2_12M>, <&ccu CLK_USBPHY2_GATE>,
				 <&ccu CLK_12M_FROM_48M>,<&ccu CLK_12M_FROM_24M>,<&ccu CLK_12M_FROM_32K>;
			clock-names = "bus_hci", "ohci", "phy","hoscx2","hosc","losc";
			resets = <&ccu RST_BUS_USBOHCI2>, <&ccu RST_BUS_USBPHY2>;
			reset-names = "hci", "phy";
			hci_ctrl_no = <2>;
		};

		disp: disp@1000000 {
		    compatible = "allwinner,sunxi-disp";
			reg = <0x0 0x01000000 0x0 0x00300000>,/*de*/
				<0x0 0x01c70000 0x0 0xfff>,/*tcon top*/
				<0x0 0x01c71000 0x0 0xfff>,/*tcon0*/
				<0x0 0x01c72000 0x0 0xfff>,/*tcon1*/
				<0x0 0x01c73000 0x0 0xfff>,/*tcon2*/
				<0x0 0x01c74000 0x0 0xfff>,/*tcon3*/
				<0x0 0x01ca0000 0x0 0x10fc>;/*dsi*/
			interrupts = <GIC_SPI 44 IRQ_TYPE_LEVEL_HIGH>,
				<GIC_SPI 45 IRQ_TYPE_LEVEL_HIGH>,
				<GIC_SPI 51 IRQ_TYPE_LEVEL_HIGH>,
				<GIC_SPI 52 IRQ_TYPE_LEVEL_HIGH>,
				<GIC_SPI 57 IRQ_TYPE_LEVEL_HIGH>;/* for dsi */
			clocks = <&ccu CLK_DE>,
				 <&ccu CLK_DE>,
				 <&ccu CLK_BUS_DE>,
				 <&ccu CLK_BUS_DE>,
				 <&ccu CLK_TCON_LCD0>,
				 <&ccu CLK_TCON_LCD1>,
				 <&ccu CLK_TCON_TV0>,
				 <&ccu CLK_TCON_TV1>,
				 <&ccu CLK_MIPI_DSI>,
				 <&ccu CLK_BUS_TCONLCD0>,
				 <&ccu CLK_BUS_TCONLCD1>,
				 <&ccu CLK_BUS_TCONTV0>,
				 <&ccu CLK_BUS_TCONTV1>,
				 <&ccu CLK_BUS_MIPIDSI>,
				 <&ccu CLK_BUS_TCONTOP>,
				 <&ccu CLK_BUS_TCONTOP>,
				 <&ccu CLK_BUS_TCONTOP>,
				 <&ccu CLK_BUS_TCONTOP>;
			clock-names = 	"clk_de0",
					"clk_de1",
					"clk_bus_de0",
					"clk_bus_de1",
					"clk_tcon0", /* tcon lcd */
					"clk_tcon1",
					"clk_tcon2", /* tcon tv */
					"clk_tcon3",
					"clk_mipi_dsi0",
					"clk_bus_tcon0",
					"clk_bus_tcon1",
					"clk_bus_tcon2",
					"clk_bus_tcon3",
					"clk_bus_mipi_dsi0",
					"clk_bus_dpss_top0",
					"clk_bus_dpss_top1",
					"clk_bus_dpss_top2",
					"clk_bus_dpss_top3";
			resets = <&ccu RST_BUS_DE>,
				 <&ccu RST_BUS_DE>,
				 <&ccu RST_BUS_TCON_LCD0>,
				 <&ccu RST_BUS_TCON_LCD1>,
				 <&ccu RST_BUS_TCON_TV0>,
				 <&ccu RST_BUS_TCON_TV1>,
				 <&ccu RST_BUS_LVDS>,
				 <&ccu RST_BUS_LVDS>,
				 <&ccu RST_BUS_MIPI_DSI>,
				 <&ccu RST_BUS_TCON_TOP>,
				 <&ccu RST_BUS_TCON_TOP>,
				 <&ccu RST_BUS_TCON_TOP>,
				 <&ccu RST_BUS_TCON_TOP>;
			reset-names = 	"rst_bus_de0",
					"rst_bus_de1",
					"rst_bus_tcon0",
					"rst_bus_tcon1",
					"rst_bus_tcon2",
					"rst_bus_tcon3",
					"rst_bus_lvds0",
					"rst_bus_lvds1",
					"rst_bus_mipi_dsi0",
					"rst_bus_dpss_top0",
					"rst_bus_dpss_top1",
					"rst_bus_dpss_top2",
					"rst_bus_dpss_top3";

			assigned-clocks = <&ccu CLK_DE>,
					  <&ccu CLK_MIPI_DSI>,
					  <&ccu CLK_TCON_LCD0>,
					  <&ccu CLK_PLL_MIPI>;
			assigned-clock-parents = <&ccu CLK_PLL_DE>,
						 <&ccu CLK_PLL_VIDEO0_1X>,
						 <&ccu CLK_PLL_MIPI>,
						 <&ccu CLK_PLL_VIDEO0_1X>;
			assigned-clock-rates = <297000000>,
					       <0>,
					       <0>,
					       <0>;
			boot_disp = <0>;
			fb_base = <0>;

			status = "okay";
		};

		drm: drm@1000000 {
			compatible = "allwinner,sunxi-drm";
			fb_base = <0>;
			status = "okay";
		};

		drm_de: de@1000000 {
			compatible = "allwinner,sunxi-de";
			reg = <0x0 0x01000000 0x0 0x00300000>; /* de */
			clocks = <&ccu CLK_DE>,
				<&ccu CLK_BUS_DE>;
			clock-names = "clk_de",
						"clk_bus_de";
			resets = <&ccu RST_BUS_DE>;
			reset-names = "rst_bus_de";
			chn_cfg_mode = <1>;
			status = "okay";
		};

		drm_tcon: tcon@1c71000 {
			compatible = "allwinner,sunxi-tcon";
			reg = <0x0 0x01c70000 0x0 0xfff>, /*tcon top*/
			<0x0 0x01c71000 0x0 0xfff>, /*tcon_lcd0*/
			<0x0 0x01c72000 0x0 0xfff>, /*tcon_lcd1*/
			<0x0 0x01c73000 0x0 0xfff>, /*tcon_tv0*/
			<0x0 0x01c74000 0x0 0xfff>; /*tcon_tv1*/
			interrupts =
			<GIC_SPI 44 IRQ_TYPE_LEVEL_HIGH>, /* tcon_lcd0 */
			<GIC_SPI 45 IRQ_TYPE_LEVEL_HIGH>, /* tcon_lcd1 */
			<GIC_SPI 51 IRQ_TYPE_LEVEL_HIGH>, /* tcon_tv0 */
			<GIC_SPI 52 IRQ_TYPE_LEVEL_HIGH>; /* tcon_tv1 */
			clocks = <&ccu CLK_BUS_TCONTOP>,
				 <&ccu CLK_TCON_LCD0>,
				 <&ccu CLK_TCON_LCD1>,
				 <&ccu CLK_TCON_TV0>,
				 <&ccu CLK_TCON_TV1>,
				 <&ccu CLK_BUS_TCONLCD0>,
				 <&ccu CLK_BUS_TCONLCD1>,
				 <&ccu CLK_BUS_TCONTV0>,
				 <&ccu CLK_BUS_TCONTV1>;
			clock-names = "clk_bus_dpss_top",
						"clk_tcon0", /* tcon lcd */
						"clk_tcon1",
						"clk_tcon2", /* tcon tv */
						"clk_tcon3",
						"clk_bus_tcon0",
						"clk_bus_tcon1",
						"clk_bus_tcon2",
						"clk_bus_tcon3";
			resets = <&ccu RST_BUS_TCON_TOP>,
					<&ccu RST_BUS_TCON_LCD0>,
					<&ccu RST_BUS_TCON_LCD1>,
					<&ccu RST_BUS_TCON_TV0>,
					<&ccu RST_BUS_TCON_TV1>;
			reset-names = "rst_bus_dpss_top",
						"rst_bus_tcon0",
						"rst_bus_tcon1",
						"rst_bus_tcon2",
						"rst_bus_tcon3";
			status = "okay";
		};

		lcdcore: lcd-core@1c0c000 {
			compatible = "allwinner,sunxi-lcd";
			reg = <0x0 0x01ca0000 0x0 0x10fc>; /* dsi */
			interrupts = <GIC_SPI 57 IRQ_TYPE_LEVEL_HIGH>; /* dsi */
			clocks = <&ccu CLK_MIPI_DSI>,
				<&ccu CLK_BUS_MIPIDSI>;
			clock-names = "clk_mipi_dsi0",
				"clk_bus_mipi_dsi0";
			resets = <&ccu RST_BUS_LVDS>,
				<&ccu RST_BUS_MIPI_DSI>;
			reset-names = "rst_bus_lvds",
				"rst_bus_mipi_dsi0";
			status = "okay";
		};

		boot_disp: boot_disp {
			compatible = "allwinner,boot_disp";
		};

		csi_cci0:cci@1cb3000 {
			compatible = "allwinner,sunxi-csi_cci";
			reg = <0x0 0x01cb3000 0x0 0x1000>;	/*0x01cb3000--0x01cb4000*/
			interrupts = <GIC_SPI 85 IRQ_TYPE_LEVEL_HIGH>;/*SUNXI_IRQ_CSI0_CCI (SUNXI_GIC_START + 85) = 117*/
			status = "okay";
		};
		csi_res0:csi_res@1c09000 {
			compatible = "allwinner,sunxi-csi";
			reg = <0x0 0x01c09000 0x0 0x1000>;/*0x01c09000--0x01c0a000*/
			clocks 				= <&ccu CLK_CSI_SCLK>, <&ccu CLK_CSI_MCLK0>,
								<&ccu CLK_PLL_PERIPH0_1X>, <&dcxo24M>,
								<&ccu CLK_PLL_VIDEO1_1X>, <&ccu CLK_BUS_CSI0>, <&ccu CLK_CSI0_GATE>;
			clock-names			= "csi_sclk", "csi_mclk0",
								"csi_sclk_src", "csi_mclk_24m",
								"csi_mclk_pll", "csi0_bus", "csi0_dclk_gating";
			clocks-index		= <0 1 0xff 2 3 0xff>;
			resets = <&ccu RST_BUS_CSI0>;
			reset-names = "csi0_ret";
			status = "okay";
		};
		csi_res1:csi_res@1c1d000 {
			compatible = "allwinner,sunxi-csi";
			reg = <0x0 0X01c1d000 0x0 0x1000>;/*0X01c1d000--0x01c0e000*/
			clocks 				= <&ccu CLK_CSI_SCLK>, /*<&ccu CLK_CSI_MCLK1>,*/
								<&ccu CLK_PLL_PERIPH0_1X>, <&dcxo24M>,
								<&ccu CLK_PLL_VIDEO1_1X>, <&ccu CLK_BUS_CSI1>, <&ccu CLK_CSI1_GATE>;
			clock-names			= "csi_sclk", "csi_mclk1",
								"csi_sclk_src", "csi_mclk_24m",
								"csi_mclk_pll", "csi1_bus", "csi1_dclk_gating";
			clocks-index		= <0 1 0xff 2 3 0xff>;
			resets = <&ccu RST_BUS_CSI1>;
			reset-names = "csi1_ret";
			status = "okay";
		};
		csi0:vfe@0 {
			device_type= "csi0";
			compatible = "allwinner,sunxi-vfe";
			interrupts = <GIC_SPI 42 IRQ_TYPE_LEVEL_HIGH>;/*SUNXI_IRQ_CSI0 (SUNXI_GIC_START + 42 ) = 74*/
			pinctrl-names 	= "default","sleep","mclk0-default","mclk0-sleep";
			pinctrl-0 		= <&csi0_pins_a>;
			pinctrl-1 		= <&csi0_pins_b>;
			pinctrl-2 		= <&csi_mclk0_pins_a>;
			pinctrl-3 		= <&csi_mclk0_pins_b>;
			cci_sel			= <0>;
			csi_sel			= <0>;
			mipi_sel		= <0>;
			isp_sel			= <0>;
			csi0_sensor_list	= <0>;
			csi0_mck 		= <>; /*PE1 .mul_sel = 1, .pull = 0, .drv_level = 1, .data = 0*/
			status = "okay";
			csi0_dev0:dev@0{
				csi0_dev0_mname         = "n5";
				csi0_dev0_twi_addr      = <0x64>;
				csi0_dev0_twi_id      	= <3>;
				csi0_dev0_pos			= "rear";
				csi0_dev0_isp_used      = <0>;
				csi0_dev0_fmt           = <0>;
				csi0_dev0_stby_mode     = <0>;
				csi0_dev0_vflip         = <0>;
				csi0_dev0_hflip         = <0>;
				csi0_dev0_iovdd-supply  = <>;
				csi0_dev0_iovdd_vol     = <3300000>;
				csi0_dev0_avdd-supply   = <>;
				csi0_dev0_avdd_vol      = <2800000>;
				csi0_dev0_dvdd-supply   = <>;
				csi0_dev0_dvdd_vol      = <1500000>;
				csi0_dev0_afvdd-supply  = <>;
				csi0_dev0_afvdd_vol     = <2800000>;
				csi0_dev0_power_en	= <>;
				csi0_dev0_reset 	= <>; /*PC20 .mul_sel = 1, .pull = 0, .drv_level = 1, .data = 0*/
				csi0_dev0_pwdn 		= <>; /*PH16 .mul_sel = 1, .pull = 0, .drv_level = 1, .data = 0*/
				csi0_dev0_flash_en	= <>;
				csi0_dev0_flash_mode	= <>;
				csi0_dev0_af_pwdn	= <>;
				csi0_dev0_act_used      = <0>;
				csi0_dev0_act_name      = "ad5820_act";
				csi0_dev0_act_slave	= <0x18>;
				status	= "okay";
			};
		};
		csi1:vfe@1 {
			device_type= "csi1";
			compatible = "allwinner,sunxi-vfe";
			interrupts = <GIC_SPI 43 IRQ_TYPE_LEVEL_HIGH>;/*SUNXI_IRQ_CSI1 (SUNXI_GIC_START + 43 ) = 75*/
			pinctrl-names 		= "default","sleep";
			pinctrl-0 		= <&csi1_pins_a>;
			pinctrl-1 		= <&csi1_pins_b>;
			pinctrl-2 		= <&csi_mclk1_pins_a>;
			pinctrl-3 		= <&csi_mclk1_pins_b>;
			cci_sel			= <0>;
			csi_sel			= <1>;
			mipi_sel		= <0>;
			isp_sel			= <0>;
			csi1_sensor_list	= <0>;
			csi1_mck 		= <>; /*PG1 .mul_sel = 1, .pull = 0, .drv_level = 1, .data = 0*/
			status = "okay";
			csi1_dev0:dev@0{
				csi1_dev0_mname         = "ov5640";
				csi1_dev0_twi_addr      = <0x78>;
				csi1_dev0_twi_id      	= <1>;
				csi1_dev0_pos		= "front";
				csi1_dev0_isp_used      = <1>;
				csi1_dev0_fmt           = <0>;
				csi1_dev0_stby_mode     = <0>;
				csi1_dev0_vflip         = <0>;
				csi1_dev0_hflip         = <0>;
				csi1_dev0_iovdd         = "iovdd-csi";
				csi1_dev0_iovdd_vol     = <2800000>;
				csi1_dev0_avdd          = "avdd-csi";
				csi1_dev0_avdd_vol      = <2800000>;
				csi1_dev0_dvdd          = "dvdd-csi-18";
				csi1_dev0_dvdd_vol      = <1500000>;
				csi1_dev0_afvdd         = "afvcc-csi";
				csi1_dev0_afvdd_vol     = <2800000>;
				csi1_dev0_power_en	= <>;
				csi1_dev0_reset 	= <>; /*PH14 .mul_sel = 1, .pull = 0, .drv_level = 1, .data = 0*/
				csi1_dev0_pwdn 		= <>; /*PH17 .mul_sel = 1, .pull = 0, .drv_level = 1, .data = 0*/
				csi1_dev0_flash_en	= <>;
				csi1_dev0_flash_mode	= <>;
				csi1_dev0_af_pwdn	= <>;
				csi1_dev0_act_used      = <0>;
				csi1_dev0_act_name      = "ad5820_act";
				csi1_dev0_act_slave	= <0x18>;
				status	= "okay";
			};
		};

		hdmi: hdmi@1ee0000 {
			compatible = "allwinner,sunxi-hdmi";
			reg = <0x0 0x01ee0000 0x0 0x20000>;
			clocks = <&ccu CLK_HDMI>,
				<&ccu CLK_HDMI_DDC_GATE>,
				<&ccu CLK_TCON_TV0>,
				<&ccu CLK_BUS_HDMI0>,
				<&ccu CLK_BUS_HDMI1>;
			clock-names = "clk_hdmi",
					"clk_ddc",
					"clk_tcon_tv0",
					"clk_bus_hdmi0",
					"clk_bus_hdmi1";
			resets = <&ccu RST_BUS_HDMI0>,
					<&ccu RST_BUS_HDMI1>;
			reset-names = "rst_bus_hdmi0",
					"rst_bus_hdmi1";
			assigned-clocks = <&ccu CLK_HDMI>;
			assigned-clock-parents = <&ccu CLK_PLL_VIDEO1_1X>;
			assigned-clock-rates = <0>;

			status = "okay";
		};

		lcd0: lcd0@1c0c000 {
			compatible = "allwinner,sunxi-lcd0";
			/* Fake registers to avoid dtc compiling warnings */
			reg = <0x0 0x1c0c000 0x0 0x0>;
			pinctrl-names = "active","sleep";
		};

		lcd1: lcd1@1c0c000 {
			compatible = "allwinner,sunxi-lcd1";
			/* Fake registers to avoid dtc compiling warnings */
			reg = <0x0 0x1c0c000 0x0 0x0>;
			pinctrl-names = "active","sleep";
		};

		tv0: tv0@1c94000 {
			compatible = "allwinner,sunxi-tv";
			reg = <0x0 0x01c90000 0x0 0x100>,
				<0x0 0x01c94000 0x0 0x3fc>;
			clocks = <&ccu CLK_BUS_TVETOP>,<&ccu CLK_TVE0>,<&ccu CLK_BUS_TVE0>;
			clock-names = "clk_bus_tve_top", "clk_tve0", "clk_bus_tve0";
			resets = <&ccu RST_BUS_TVE_TOP>,<&ccu RST_BUS_TVE0>;
			reset-names = "rst_bus_tve_top", "rst_bus_tve";
			assigned-clocks = <&ccu CLK_TVE0>;
			assigned-clock-parents = <&ccu CLK_PLL_VIDEO0_1X>;
			device_type = "tv0";
			pinctrl-names = "active","sleep";
			status = "disabled";
		};

		tv1: tv1@1c98000 {
			compatible = "allwinner,sunxi-tv";
			reg = <0x0 0x01c90000 0x0 0x100>,
				<0x0 0x01c98000 0x0 0x3fc>;
			clocks = <&ccu CLK_BUS_TVETOP>,<&ccu CLK_TVE1>,<&ccu CLK_BUS_TVE1>;
			clock-names = "clk_bus_tve_top", "clk_tve1", "clk_bus_tve1";
			resets = <&ccu RST_BUS_TVE_TOP>,<&ccu RST_BUS_TVE1>;
			reset-names = "rst_bus_tve_top", "rst_bus_tve";
			assigned-clocks = <&ccu CLK_TVE1>;
			assigned-clock-parents = <&ccu CLK_PLL_VIDEO0_1X>;
			device_type = "tv1";
			pinctrl-names = "active","sleep";
			status = "disabled";
		};

		tvd: tvd@1c30000 {
			compatible = "allwinner,sunxi-tvd";
			reg = <0x0 0x01c30000 0x0 0x00010000>;/*tvd_top*/
			clocks = <&ccu CLK_BUS_TVDTOP>,<&ccu CLK_TVD_GATE>;
			clock-names = "clk_bus_tvd_top","clk_mbus_tvd";
			resets = <&ccu RST_BUS_TVD_TOP>;
			reset-names = "rst_bus_tvd_top";
			interrupts = <GIC_SPI 61 IRQ_TYPE_LEVEL_HIGH>;
			tvd-number = <4>;
			tvds = <&tvd0>, <&tvd1>, <&tvd2>, <&tvd3>;
			status = "okay";
		};

		tvd0: tvd0@1c31000 {
			compatible = "allwinner,sunxi-tvd0";
			reg = <0x0 0x01c31000 0x0 0x00010000>;
			interrupts = <GIC_SPI 97 IRQ_TYPE_LEVEL_HIGH>;
			clocks = <&ccu CLK_TVD0>,<&ccu CLK_BUS_TVD0>;
			clock-names = "clk_tvd0", "clk_bus_tvd0";
			resets = <&ccu RST_BUS_TVD0>;
			reset-names = "rst_bus_tvd0";
			status = "okay";
		};

		tvd1: tvd1@1c32000 {
			compatible = "allwinner,sunxi-tvd1";
			reg = <0x0 0x01c32000 0x0 0x00010000>;
			interrupts = <GIC_SPI 98 IRQ_TYPE_LEVEL_HIGH>;
			clocks = <&ccu CLK_TVD1>,<&ccu CLK_BUS_TVD1>;
			clock-names = "clk_tvd1", "clk_bus_tvd1";
			resets = <&ccu RST_BUS_TVD1>;
			reset-names = "rst_bus_tvd1";
			status = "okay";
		};

		tvd2: tvd2@1c33000 {
			compatible = "allwinner,sunxi-tvd2";
			reg = <0x0 0x01c33000 0x0 0x00010000>;
			interrupts = <GIC_SPI 99 IRQ_TYPE_LEVEL_HIGH>;
			clocks = <&ccu CLK_TVD2>,<&ccu CLK_BUS_TVD2>;
			clock-names = "clk_tvd2", "clk_bus_tvd2";
			resets = <&ccu RST_BUS_TVD2>;
			reset-names = "rst_bus_tvd2";
			status = "okay";
		};

		tvd3: tvd3@1c34000 {
			compatible = "allwinner,sunxi-tvd3";
			reg = <0x0 0x01c34000 0x0 0x00010000>;
			interrupts = <GIC_SPI 100 IRQ_TYPE_LEVEL_HIGH>;
			clocks = <&ccu CLK_TVD3>,<&ccu CLK_BUS_TVD3>;
			clock-names = "clk_tvd3", "clk_bus_tvd3";
			resets = <&ccu RST_BUS_TVD3>;
			reset-names = "rst_bus_tvd3";
			status = "okay";
		};
		sid@1c1b000 {
			compatible = "allwinner,sun8iw11p1-sid", "allwinner,sunxi-sid";
			reg = <0x0 0x01c1b000 0 0x1000>;
			#address-cells = <1>;
			#size-cells = <1>;

			speedbin_efuse: speed@00 {
				reg = <0x0 2>;
			};

			ths_calib: calib@14 {
				reg = <0x14 8>;
			};

			cpubin_efuse: calib@1c {
				reg = <0x1c 2>;
			};

			cpubin_extend: calib@28 {
				reg = <0x28 2>;
			};

			chipid {
				reg = <0x0 0>;
				offset = <0x200>;
				size = <0x10>;
			};
		};


		sram_ctrl: sram_ctrl@1c00000 {
			compatible = "allwinner,sram_ctrl";
			reg = <0x0 0x01c00000 0 0xf4>;
			soc_ver {
				offset = <0x24>;
				mask = <0xff>;
				shift = <0>;
				ver_a = <0x17010000>;
				ver_b = <0x17010001>;
			};

			soc_id {
				offset = <0x200>;
				mask = <0x1>;
				shift = <22>;
			};

			soc_bin {
				offset = <0x0>;
				mask = <0x3ff>;
				shift = <0x0>;
			};
		};

		/* audio dirver module -> audio codec */
		codec:codec@1c22c00 {
			#sound-dai-cells = <0>;
			compatible	= "allwinner,sunxi-snd-codec";
			reg		= <0x0 0x01c22c00 0x0 0x300>;
			resets		= <&ccu RST_BUS_AC>;
			clocks		= <&ccu CLK_BUS_AC_DIG>,
					  <&ccu CLK_PLL_AUDIO>,
					  <&ccu CLK_AC_DIGITAL_GATE>;
			clock-names	= "clk_bus_audio",
					  "clk_pll_audio",
					  "clk_ac_digital_gate";
			status = "disabled";
		};

		codec_plat:codec_plat {
			#sound-dai-cells = <0>;
			compatible	= "allwinner,sunxi-snd-plat-aaudio";
			adc-txdata	= <0x01c22c18>;
			dac-txdata	= <0x01c22c20>;
			dmas		= <&dma 19>, <&dma 19>;
			dma-names	= "tx", "rx";
			playback-cma	= <128>;
			capture-cma	= <128>;
			tx-fifo-size	= <128>;
			rx-fifo-size	= <128>;
			status = "disabled";
		};

		codec_mach:codec_mach {
			compatible = "allwinner,sunxi-snd-mach";
			soundcard-mach,name		= "audiocodec";
			soundcard-mach,pin-switches	= "MIC1", "MIC2", "FMIN", "LINEIN",
							  "HPOUT", "PHONEOUT", "SPK";
			soundcard-mach,routing		= "MIC1_PIN",	"MIC1",
							  "MIC2_PIN",	"MIC2",
							  "FMINL_PIN",	"FMIN",
							  "FMINR_PIN",	"FMIN",
							  "LINEINL_PIN","LINEIN",
							  "LINEINR_PIN","LINEIN",
							  "HPOUT",	"HPOUTL_PIN",
							  "HPOUT",	"HPOUTR_PIN",
							  "PHONEOUT",	"PHONEOUTP_PIN",
							  "PHONEOUT",	"PHONEOUTN_PIN",
							  "SPK",	"HPOUTL_PIN",
							  "SPK",	"HPOUTR_PIN",
							  "SPK",	"PHONEOUTP_PIN",
							  "SPK",	"PHONEOUTN_PIN";
			status = "disabled";
			soundcard-mach,cpu {
				sound-dai = <&codec_plat>;
			};
			soundcard-mach,codec {
				sound-dai = <&codec>;
				soundcard-mach,pll-fs	= <1>;
			};
		};

		/* audio dirver module -> hdmi codec */
		hdmi_codec:hdmi_codec {
			#sound-dai-cells = <0>;
			compatible	= "allwinner,sunxi-snd-codec-hdmi";
			status = "disabled";
		};

		/* audio dirver module -> owa */
		owa_plat:owa_plat@1c21000 {
			#sound-dai-cells = <0>;
			compatible	= "allwinner,sun8iw11-owa";
			reg		= <0x0 0x01c21000 0x0 0x38>;
			resets		= <&ccu RST_BUS_SPDIF>;
			clocks		= <&ccu CLK_BUS_SPDIF>,
					  <&ccu CLK_PLL_AUDIO>,
					  <&ccu CLK_SPDIF>;
			clock-names	= "clk_bus_owa",
					  "clk_pll_audio",
					  "clk_owa";
			dmas		= <&dma 2>, <&dma 2>;
			dma-names	= "tx", "rx";
			playback-cma	= <128>;
			capture-cma	= <128>;
			tx-fifo-size	= <128>;
			rx-fifo-size	= <128>;
			status = "disabled";
		};

		owa_mach:owa_mach {
			compatible = "allwinner,sunxi-snd-mach";
			soundcard-mach,name = "sndowa";
			status = "disabled";
			soundcard-mach,cpu {
				sound-dai = <&owa_plat>;
			};
			soundcard-mach,codec {
			};
		};

		/* audio dirver module -> I2S/PCM */
		i2s0_plat:i2s0_plat@1c22000 {
			#sound-dai-cells = <0>;
			compatible = "allwinner,sun8iw11-i2s";
			reg		= <0x0 0x01C22000 0x0 0x58>;
			resets		= <&ccu RST_BUS_DAUDIO0>;
			clocks		= <&ccu CLK_BUS_DAUDIO0>,
					  <&ccu CLK_PLL_AUDIO>,
					  <&ccu CLK_DAUDIO0>;
			clock-names	= "clk_bus_i2s",
					  "clk_pll_audio",
					  "clk_i2s";
			dmas		= <&dma 3>, <&dma 3>;
			dma-names	= "tx", "rx";
			playback-cma	= <128>;
			capture-cma	= <128>;
			tx-fifo-size	= <128>;
			rx-fifo-size	= <128>;
			status = "disabled";
		};

		i2s0_mach:i2s0_mach {
			compatible = "allwinner,sunxi-snd-mach";
			soundcard-mach,name		= "sndi2s0";
			soundcard-mach,format		= "i2s";
			soundcard-mach,slot-num		= <2>;
			soundcard-mach,slot-width	= <32>;
			status = "disabled";
			soundcard-mach,cpu {
				sound-dai = <&i2s0_plat>;
			};
			soundcard-mach,codec {
			};
		};

		i2s1_plat:i2s1_plat@1c22400 {
			#sound-dai-cells = <0>;
			compatible = "allwinner,sun8iw11-i2s";
			reg		= <0x0 0x01C22400 0x0 0x58>;
			resets		= <&ccu RST_BUS_DAUDIO1>;
			clocks		= <&ccu CLK_BUS_DAUDIO1>,
					  <&ccu CLK_PLL_AUDIO>,
					  <&ccu CLK_DAUDIO1>;
			clock-names	= "clk_bus_i2s",
					  "clk_pll_audio",
					  "clk_i2s";
			dmas		= <&dma 4>, <&dma 4>;
			dma-names	= "tx", "rx";
			playback-cma	= <128>;
			capture-cma	= <128>;
			tx-fifo-size	= <128>;
			rx-fifo-size	= <128>;
			status = "disabled";
		};

		i2s1_mach:i2s1_mach {
			compatible = "allwinner,sunxi-snd-mach";
			soundcard-mach,name		= "sndi2s1";
			soundcard-mach,format		= "i2s";
			soundcard-mach,slot-num		= <2>;
			soundcard-mach,slot-width	= <32>;
			status = "disabled";
			soundcard-mach,cpu {
				sound-dai = <&i2s1_plat>;
			};
			soundcard-mach,codec {
			};
		};

		i2s2_plat:i2s2_plat@1c22800 {
			#sound-dai-cells = <0>;
			compatible = "allwinner,sun8iw11-i2s";
			reg		= <0x0 0x01C22800 0x0 0x58>;
			resets		= <&ccu RST_BUS_DAUDIO2>;
			clocks		= <&ccu CLK_BUS_DAUDIO2>,
					  <&ccu CLK_PLL_AUDIO>,
					  <&ccu CLK_DAUDIO2>;
			clock-names	= "clk_bus_i2s",
					  "clk_pll_audio",
					  "clk_i2s";
			dmas		= <&dma 6>, <&dma 6>;
			dma-names	= "tx", "rx";
			playback-cma	= <128>;
			capture-cma	= <128>;
			tx-fifo-size	= <128>;
			rx-fifo-size	= <128>;
			status = "disabled";
		};

		i2s2_mach:i2s2_mach{
			compatible = "allwinner,sunxi-snd-mach";
			soundcard-mach,name		= "sndhdmi";
			soundcard-mach,format		= "i2s";
			soundcard-mach,slot-num		= <2>;
			soundcard-mach,slot-width	= <32>;
			status = "disabled";
			soundcard-mach,cpu {
				sound-dai = <&i2s2_plat>;
			};
			soundcard-mach,codec {
			};
		};

		ir0: ir@1c21800 {
			compatible = "allwinner,irrx";
			reg = <0x0 0x01c21800 0x0 0x400>;
			interrupts = <GIC_SPI 5 IRQ_TYPE_LEVEL_HIGH>;
			clocks = <&ccu CLK_BUS_IR0>, <&dcxo24M>, <&ccu CLK_IR0>;
			clock-names = "bus", "pclk", "mclk";
			resets = <&ccu RST_BUS_IR>;
			status = "disabled";
		};

		ir1: ir@1c21c00 {
			compatible = "allwinner,irrx";
			reg = <0x0 0x01c21c00 0x0 0x400>;
			interrupts = <GIC_SPI 6 IRQ_TYPE_LEVEL_HIGH>;
			clocks = <&ccu CLK_BUS_IR1>, <&dcxo24M>, <&ccu CLK_IR1>;
			clock-names = "bus", "pclk", "mclk";
			resets = <&ccu RST_BUS_IR1>;
			status = "disabled";
		};

		sata:sata@1c18000{
			#address-cells = <1>;
			#size-cells = <0>;
			compatible = "allwinner,sun8i-sata";
			device_type = "sata";
			reg = <0x0 0x01c18000 0x0 0x200>;
			interrupts = <GIC_SPI 56 IRQ_TYPE_LEVEL_HIGH>;
			clocks = <&ccu CLK_PLL_SATA>, <&ccu CLK_SATA>, <&ccu CLK_BUS_SATA>;
			clock-names = "pll", "mod", "bus";
			resets = <&ccu RST_BUS_SATA>;
			status = "disabled";

			sata-port@0 {
				reg = <0>;
			};
		};

		rfkill: rfkill {
			compatible = "allwinner,sunxi-rfkill";
			status = "disabled";
		};

		addr_mgt: addr_mgt {
			compatible = "allwinner,sunxi-addr_mgt";
			status = "disabled";
		};

		btlpm: btlpm {
			compatible = "allwinner,sunxi-btlpm";
			status = "disabled";
		};
	};
};
